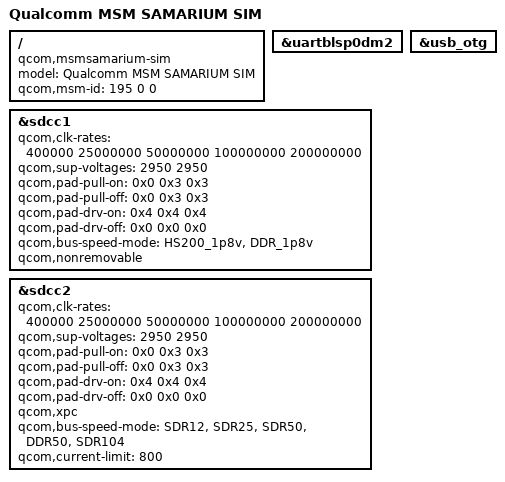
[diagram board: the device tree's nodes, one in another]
/* Copyright (c) 2013, The Linux Foundation. All rights reserved.
 *
 * This program is free software; you can redistribute it and/or modify
 * it under the terms of the GNU General Public License version 2 and
 * only version 2 as published by the Free Software Foundation.
 *
 * This program is distributed in the hope that it will be useful,
 * but WITHOUT ANY WARRANTY; without even the implied warranty of
 * MERCHANTABILITY or FITNESS FOR A PARTICULAR PURPOSE.  See the
 * GNU General Public License for more details.
 */

/dts-v1/;

/include/ "msmsamarium.dtsi"

/ {
	model = "Qualcomm MSM SAMARIUM SIM";
	compatible = "qcom,msmsamarium-sim", "qcom,msmsamarium", "qcom,sim";
	qcom,msm-id = <195 0 0>;
};

&uartblsp0dm2{
	status = "ok";
};

&sdcc1 {
	qcom,clk-rates = <400000 25000000 50000000 100000000 200000000>;
	qcom,sup-voltages = <2950 2950>;

	qcom,pad-pull-on = <0x0 0x3 0x3>; /* no-pull, pull-up, pull-up */
	qcom,pad-pull-off = <0x0 0x3 0x3>; /* no-pull, pull-up, pull-up */
	qcom,pad-drv-on = <0x4 0x4 0x4>; /* 10mA, 10mA, 10mA */
	qcom,pad-drv-off = <0x0 0x0 0x0>; /* 2mA, 2mA, 2mA */

	qcom,bus-speed-mode = "HS200_1p8v", "DDR_1p8v";
	qcom,nonremovable;
	status = "ok";
};

&sdcc2 {
	qcom,clk-rates = <400000 25000000 50000000 100000000 200000000>;
	qcom,sup-voltages = <2950 2950>;

	qcom,pad-pull-on = <0x0 0x3 0x3>; /* no-pull, pull-up, pull-up */
	qcom,pad-pull-off = <0x0 0x3 0x3>; /* no-pull, pull-up, pull-up */
	qcom,pad-drv-on = <0x4 0x4 0x4>; /* 10mA, 10mA, 10mA */
	qcom,pad-drv-off = <0x0 0x0 0x0>; /* 2mA, 2mA, 2mA */

	qcom,xpc;
	qcom,bus-speed-mode = "SDR12", "SDR25", "SDR50", "DDR50", "SDR104";
	qcom,current-limit = <800>;

	status = "ok";
};

&usb_otg {
	status = "ok";
};
